# AVR128DA64S register map
Vendor: Atmel; File version: 1.0
CPU: other r0p0, little endian, no MPU, no FPU, 4 interrupt priority bits
Registers are 8-bit, read-write, reset 0x0 unless marked. A register's access mark holds for its fields unless they carry their own. Offsets are from the block's base; [hi:lo] are bit positions.

## PORTMUX — Port Multiplexer
Base 0x008005E0
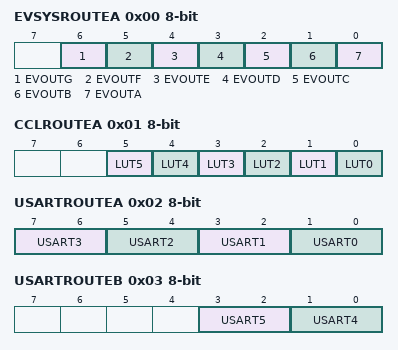
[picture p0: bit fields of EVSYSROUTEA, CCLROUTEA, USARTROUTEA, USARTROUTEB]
0x00 EVSYSROUTEA
  [6] EVOUTG — Event Output G
    0=DEFAULT (EVOUT: PG2); 1=ALT1 (EVOUT: PG7)
  [5] EVOUTF — Event Output F
    0=DEFAULT (EVOUT: PF2)
  [4] EVOUTE — Event Output E
    0=DEFAULT (EVOUT: PE2); 1=ALT1 (EVOUT: PE7)
  [3] EVOUTD — Event Output D
    0=DEFAULT (EVOUT: PD2); 1=ALT1 (EVOUT: PD7)
  [2] EVOUTC — Event Output C
    0=DEFAULT (EVOUT: PC2); 1=ALT1 (EVOUT: PC7)
  [1] EVOUTB — Event Output B
    0=DEFAULT (EVOUT: PB2); 1=ALT1 (EVOUT: PB7)
  [0] EVOUTA — Event Output A
    0=DEFAULT (EVOUT: PA2); 1=ALT1 (EVOUT: PA7)
0x01 CCLROUTEA
  [5] LUT5 — CCL Look-Up Table 5 Signals
    0=DEFAULT (In: PG0, PG1, PG2 Out: PG3); 1=ALT1 (In: PG0, PG1, PG2 Out: PG6)
  [4] LUT4 — CCL Look-Up Table 4 Signals
    0=DEFAULT (In: PB0, PB1, PB2 Out: PB3); 1=ALT1 (In: PB0, PB1, PB2 Out: PB6)
  [3] LUT3 — CCL Look-Up Table 3 Signals
    0=DEFAULT (In: PF0, PF1, PF2 Out: PF3)
  [2] LUT2 — CCL Look-Up Table 2 Signals
    0=DEFAULT (In: PD0, PD1, PD2 Out: PD3); 1=ALT1 (In: PD0, PD1, PD2 Out: PD6)
  [1] LUT1 — CCL Look-Up Table 1 Signals
    0=DEFAULT (In: PC0, PC1, PC2 Out: PC3); 1=ALT1 (In: PC0, PC1, PC2 Out: PC6)
  [0] LUT0 — CCL Look-Up Table 0 Signals
    0=DEFAULT (In: PA0, PA1, PA2 Out: PA3); 1=ALT1 (In: PA0, PA1, PA2 Out: PA6)
0x02 USARTROUTEA
  [7:6] USART3 — USART3 Signals
    0=DEFAULT (TxD: PB0, RxD: PB1, XCK: PB2, XDIR: PB3); 1=ALT1 (TxD: PB4, RxD: PB5, XCK: PB6, XDIR: PB7); 3=NONE (Not connected to any pins)
  [5:4] USART2 — USART2 Signals
    0=DEFAULT (TxD: PF0, RxD: PF1, XCK: PF2, XDIR: PF3); 1=ALT1 (TxD: PF4, RxD: PF5, XCK: -, XDIR: -); 3=NONE (Not connected to any pins)
  [3:2] USART1 — USART1 Signals
    0=DEFAULT (TxD: PC0, RxD: PC1, XCK: PC2, XDIR: PC3); 1=ALT1 (TxD: PC4, RxD: PC5, XCK: PC6, XDIR: PC7); 3=NONE (Not connected to any pins)
  [1:0] USART0 — USART0 Signals
    0=DEFAULT (TxD: PA0, RxD: PA1, XCK: PA2, XDIR: PA3); 1=ALT1 (TxD: PA4, RxD: PA5, XCK: PA6, XDIR: PA7); 3=NONE (Not connected to any pins)
0x03 USARTROUTEB
  [3:2] USART5 — USART5 Signals
    0=DEFAULT (TxD: PG0, RxD: PG1, XCK: PG2, XDIR: PG3); 1=ALT1 (TxD: PG4, RxD: PG5, XCK: PG6, XDIR: PG7); 3=NONE (Not connected to any pins)
  [1:0] USART4 — USART4 Signals
    0=DEFAULT (TxD: PE0, RxD: PE1, XCK: PE2, XDIR: PE3); 1=ALT1 (TxD: PE4, RxD: PE5, XCK: PE6, XDIR: PE7); 3=NONE (Not connected to any pins)
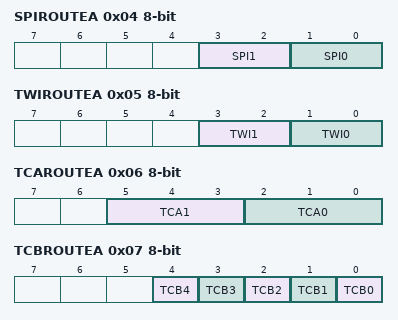
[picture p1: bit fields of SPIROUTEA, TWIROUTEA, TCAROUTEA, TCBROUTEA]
0x04 SPIROUTEA
  [3:2] SPI1 — SPI1 Signals
    0=DEFAULT (MOSI: PC0, MISO: PC1, SCK: PC2, SS: PC3); 1=ALT1 (MOSI: PC4, MISO: PC5, SCK: PC6, SS: PC7); 2=ALT2 (MOSI: PB4, MISO: PB5, SCK: PB6, SS: PB7); 3=NONE (Not connected to any pins)
  [1:0] SPI0 — SPI0 Signals
    0=DEFAULT (MOSI: PA4, MISO: PA5, SCK: PA6, SS: PA7); 1=ALT1 (MOSI: PE0, MISO: PE1, SCK: PE2, SS: PE3); 2=ALT2 (MOSI: PG4, MISO: PG5, SCK: PG6, SS: PG7); 3=NONE (Not connected to any pins)
0x05 TWIROUTEA
  [3:2] TWI1 — TWI1 Signals
    0=DEFAULT (SDA: PF2, SCL: PF3. Dual mode: SDA: PB2, SCL: PB3.); 1=ALT1 (SDA: PF2, SCL: PF3. Dual mode: SDA: PB6, SCL: PB7.); 2=ALT2 (SDA: PB2, SCL: PB3. Dual mode: SDA: PB6, SCL: PB7.)
  [1:0] TWI0 — TWI0 Signals
    0=DEFAULT (SDA: PA2, SCL: PA3. Dual mode: SDA: PC2, SCL: PC3.); 1=ALT1 (SDA: PA2, SCL: PA3. Dual mode: SDA: PC6, SCL: PC7.); 2=ALT2 (SDA: PC2, SCL: PC3. Dual mode: SDA: PC6, SCL: PC7.)
0x06 TCAROUTEA
  [5:3] TCA1 — TCA1 Signals
    0=PORTB (WOn: PB0, PB1, PB2, PB3, PB4, PB5); 1=PORTC (WOn: PC4, PC5, PC6, -, -, -); 2=PORTE (WOn: PE4, PE5, PE6, -, -, -); 3=PORTG (WOn: PG0, PG1, PG2, PG3, PG4, PG5)
  [2:0] TCA0 — TCA0 Signals
    0=PORTA (WOn: PA0, PA1, PA2, PA3, PA4, PA5); 1=PORTB (WOn: PB0, PB1, PB2, PB3, PB4, PB5); 2=PORTC (WOn: PC0, PC1, PC2, PC3, PC4, PC5); 3=PORTD (WOn: PD0, PD1, PD2, PD3, PD4, PD5); 4=PORTE (WOn: PE0, PE1, PE2, PE3, PE4, PE5); 5=PORTF (WOn: PF0, PF1, PF2, PF3, PF4, PF5); 6=PORTG (WOn: PG0, PG1, PG2, PG3, PG4, PG5)
0x07 TCBROUTEA
  [4] TCB4 — TCB4 Output
    0=DEFAULT (WO: PG3); 1=ALT1 (WO: PC6)
  [3] TCB3 — TCB3 Output
    0=DEFAULT (WO: PB5); 1=ALT1 (WO: PC1)
  [2] TCB2 — TCB2 Output
    0=DEFAULT (WO: PC0); 1=ALT1 (WO: PB4)
  [1] TCB1 — TCB1 Output
    0=DEFAULT (WO: PA3); 1=ALT1 (WO: PF5)
  [0] TCB0 — TCB0 Output
    0=DEFAULT (WO: PA2); 1=ALT1 (WO: PF4)
0x08 TCDROUTEA
  [2:0] TCD0 — TCD0 Signals
    0=DEFAULT (WOx: PA4, PA5, PA6, PA7); 1=ALT1 (WOx: PB4, PB5, PB6, PB7); 2=ALT2 (WOx: PF0, PF1, PF2, PF3); 3=ALT3 (WOx: PG4, PG5, PG6, PG7)
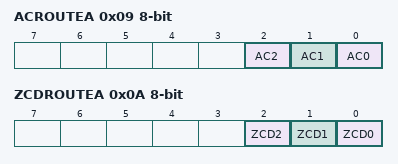
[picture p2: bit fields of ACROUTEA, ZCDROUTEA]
0x09 ACROUTEA
  [all] fields
    0=DEFAULT (OUT: PA7); 1=ALT1 (OUT: PC6)
  [2] AC2 — Analog Comparator 2 Output
  [1] AC1 — Analog Comparator 1 Output
  [0] AC0 — Analog Comparator 0 Output
0x0A ZCDROUTEA
  [all] fields
    0=DEFAULT (OUT: PA7); 1=ALT1 (OUT: PC7)
  [2] ZCD2 — Zero Cross Detector 2 Output
  [1] ZCD1 — Zero Cross Detector 1 Output
  [0] ZCD0 — Zero Cross Detector 0 Output
